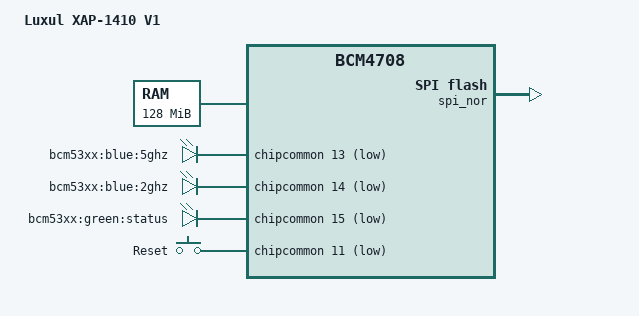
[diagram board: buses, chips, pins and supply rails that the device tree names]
/*
 * Copyright 2017 Luxul Inc.
 *
 * Licensed under the ISC license.
 */

/dts-v1/;

#include "bcm47081.dtsi"

/ {
	compatible = "luxul,xap-1410v1", "brcm,bcm47081", "brcm,bcm4708";
	model = "Luxul XAP-1410 V1";

	chosen {
		bootargs = "console=ttyS0,115200";
	};

	memory {
		reg = <0x00000000 0x08000000>;
	};

	leds {
		compatible = "gpio-leds";

		5ghz {
			label = "bcm53xx:blue:5ghz";
			gpios = <&chipcommon 13 GPIO_ACTIVE_LOW>;
			linux,default-trigger = "none";
		};

		2ghz {
			label = "bcm53xx:blue:2ghz";
			gpios = <&chipcommon 14 GPIO_ACTIVE_LOW>;
			linux,default-trigger = "none";
		};

		status {
			label = "bcm53xx:green:status";
			gpios = <&chipcommon 15 GPIO_ACTIVE_LOW>;
			linux,default-trigger = "timer";
		};
	};

	gpio-keys {
		compatible = "gpio-keys";
		#address-cells = <1>;
		#size-cells = <0>;

		restart {
			label = "Reset";
			linux,code = <KEY_RESTART>;
			gpios = <&chipcommon 11 GPIO_ACTIVE_LOW>;
		};
	};
};

&spi_nor {
	status = "okay";
};
